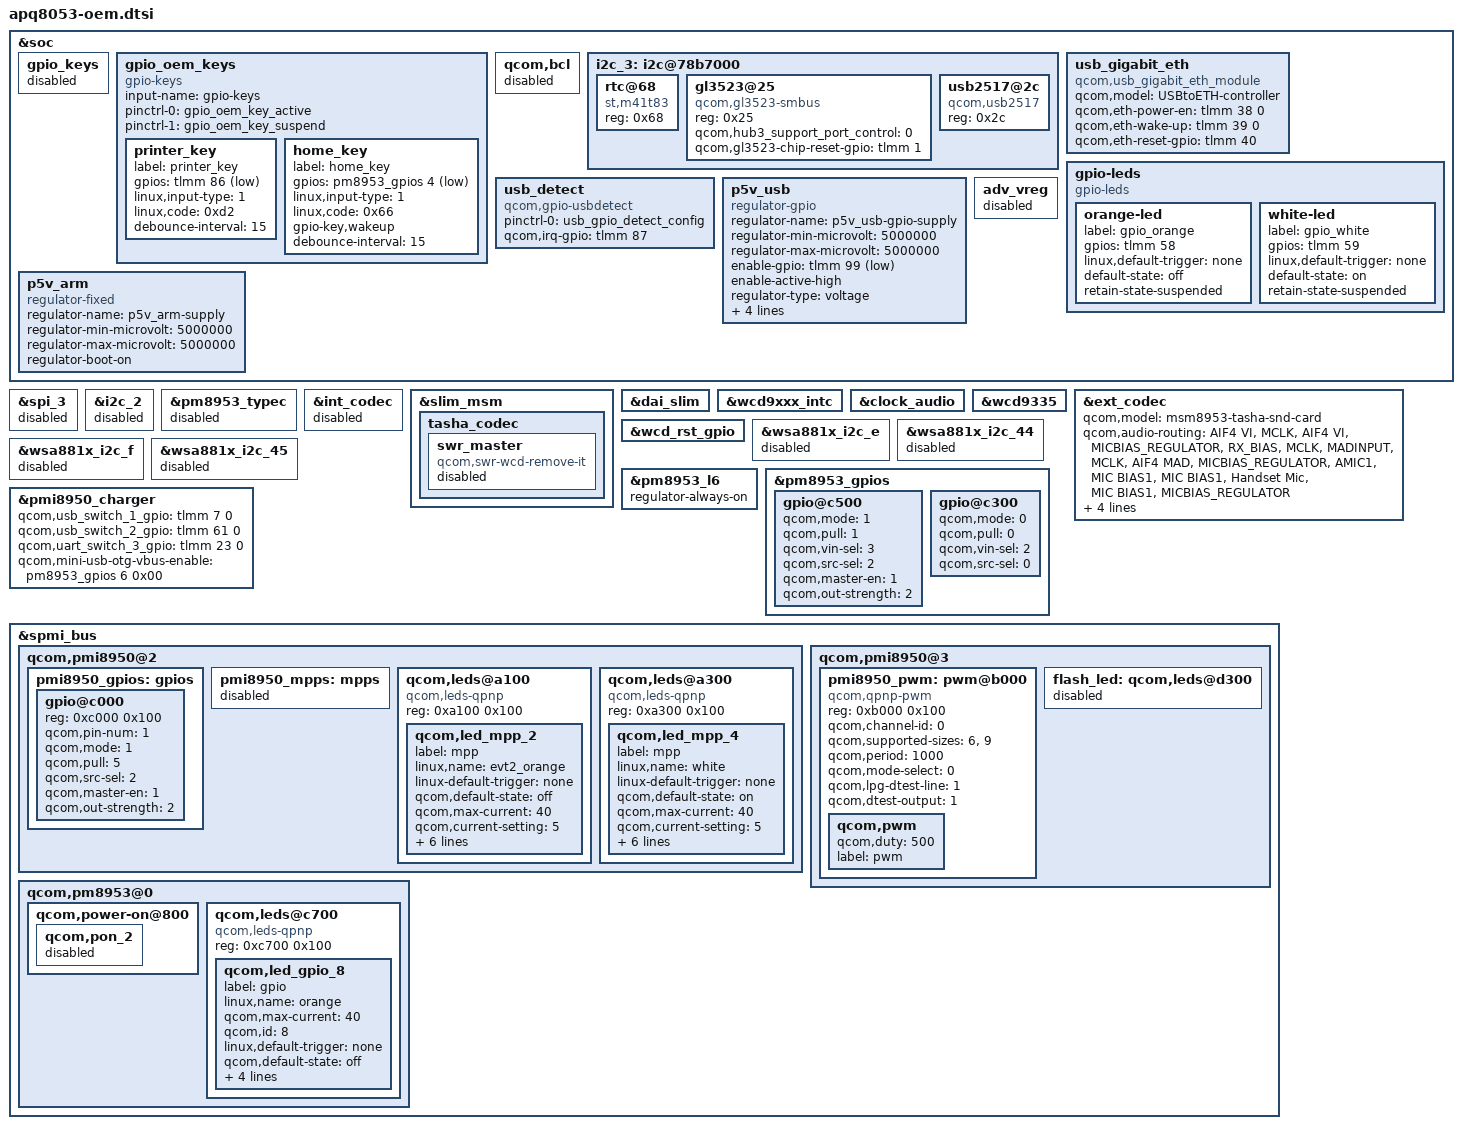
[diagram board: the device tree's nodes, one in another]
/*
 * Copyright (c) 2015-2016, The Linux Foundation. All rights reserved.
 *
 * This program is free software; you can redistribute it and/or modify
 * it under the terms of the GNU General Public License version 2 and
 * only version 2 as published by the Free Software Foundation.
 *
 * This program is distributed in the hope that it will be useful,
 * but WITHOUT ANY WARRANTY; without even the implied warranty of
 * MERCHANTABILITY or FITNESS FOR A PARTICULAR PURPOSE.  See the
 * GNU General Public License for more details.
 */


&soc {

/* Adil.Zhu, 2017/03/01, add dts info for home-key and printer-key {*/
	gpio_keys {
		status = "disabled";
	};

	gpio_oem_keys {
		compatible = "gpio-keys";
		input-name = "gpio-keys";
		pinctrl-names = "tlmm_gpio_key_active","tlmm_gpio_key_suspend";
		pinctrl-0 = <&gpio_oem_key_active>;
		pinctrl-1 = <&gpio_oem_key_suspend>;

		printer_key {
			label = "printer_key";
			gpios = <&tlmm 86 0x1>;
			linux,input-type = <1>;
			linux,code = <0xd2>; // 210 - KEY_PRINT
			debounce-interval = <15>;
		};

		home_key {
			label = "home_key";
			gpios = <&pm8953_gpios 4 0x1>;
			linux,input-type = <1>;
			linux,code = <0x66>; // 102
			gpio-key,wakeup;
			debounce-interval = <15>;
		};
	};

/* Adil.Zhu, 2017/03/01, add dts info for home-key and printer-key }*/

	/*20170308,Tony.L.Cai,disable BCL{*/
	qcom,bcl {
		status = "disabled";
	};
	/*}20170308,Tony.L.Cai,disable BCL*/

	i2c_3: i2c@78b7000 { /* BLSP1 QUP3 */
	status = "okay";

		/* OEM 2017/01/11, Jack W Lu, add RTC m41t83{ */
		rtc@68 {
			compatible = "st,m41t83";
			reg = <0x68>;
		};
		/* OEM 2017/01/11, Jack W Lu, add RTC m41t83} */
	};

/* OEM, Jerry.Zhai, 2017/09/12, usb gigabit ethernet pwr control {*/
	usb_gigabit_eth {
		compatible = "qcom,usb_gigabit_eth_module";
		qcom,model = "USBtoETH-controller";
		qcom,eth-power-en = <&tlmm 38 0>;  /* USB Gigabit Ethernet vbus pin: High enable*/
		qcom,eth-wake-up = <&tlmm 39 0>;  /* USB Gigabit Ethernet wakeup pin: Low Active*/
		qcom,eth-reset-gpio = <&tlmm 40 0>;  /* USB Gigabit Ethernet reset pin: Low Active*/
	};
/* OEM, Jerry.Zhai, 2017/01/09, usb gigabit ethernet pwr control }*/

/* pp, Tony.L.Cai, 2017/03/23, gpio leds porting{*/

	gpio-leds {
		compatible = "gpio-leds";

		orange-led {
			label="gpio_orange";
			gpios = <&tlmm 58 0>;
			linux,default-trigger = "none";
			default-state = "off";
			retain-state-suspended;
		};

		white-led {
			label="gpio_white";
			gpios = <&tlmm 59 0>;
			linux,default-trigger = "none";
			default-state = "on";
			retain-state-suspended;
		};
	};
/* pp, Tony.L.Cai, 2017/03/23, gpio leds porting}*/

	/* Carl add for vbus detect on gpio87 {*/
	usb_detect{
		compatible = "qcom,gpio-usbdetect";
		pinctrl-names = "default";
		pinctrl-0 = <&usb_gpio_detect_config>;

		qcom,irq-gpio = <&tlmm 87 0>;
	};
	/* Carl add for vbus detect on gpio87 }*/

/*pp, tony.l.cai, 20170605, gpio regulator enable for p5v_usb{*/
	p5v_usb: p5v_usb{
		compatible = "regulator-gpio";
		regulator-name = "p5v_usb-gpio-supply";
		regulator-min-microvolt = <5000000>;
		regulator-max-microvolt = <5000000>;
		enable-gpio = <&tlmm 99 1>;
		enable-active-high;
		regulator-type= "voltage";
		enable-at-boot;
		regulator-boot-on;
		gpios = <0>;
		states = <5000000 0x1
							0 0x0>;
	};
/*}pp, tony.l.cai, 20170605, gpio regulator enable for p5v_usb*/

/*OEM, Terry.Yan, 20171127, add fixed regulator for p5v_arm (RTC/HDMI){*/
	p5v_arm: p5v_arm {
		compatible = "regulator-fixed";
		regulator-name = "p5v_arm-supply";
		regulator-min-microvolt = <5000000>;
		regulator-max-microvolt = <5000000>;
		regulator-boot-on;
	};
/*OEM, Terry.Yan, 20171127, add fixed regulator for p5v_arm (RTC/HDMI){*/

/*OEM, Terry.Yan, 20171106, disable adv_vreg that controled by PM8953 GPIO 5 {*/
	adv_vreg: adv_vreg {
		status = "disabled";
	};
/*OEM, Terry.Yan, 20171106, disable adv_vreg that controled by PM8953 GPIO 5 }*/
};


&spi_3 {
	status = "disabled";
};

&i2c_2 {
	status = "disabled";
};

&pm8953_typec {
	status = "disabled";
};

/*20161208 Jack W Lu: Add for audio setting {*/
&int_codec {
	status = "disabled";
};

&slim_msm {
	status = "okay";
};

&dai_slim {
	status = "okay";
};

&wcd9xxx_intc {
	status = "okay";
};

&clock_audio {
	status = "okay";
};

&wcd9335 {
	status = "okay";
};

&ext_codec {
	qcom,model = "msm8953-tasha-snd-card";

	qcom,audio-routing =
		"AIF4 VI", "MCLK",
		"AIF4 VI", "MICBIAS_REGULATOR",
		"RX_BIAS", "MCLK",
		"MADINPUT", "MCLK",
		"AIF4 MAD", "MICBIAS_REGULATOR",
		"AMIC1", "MIC BIAS1",
		"MIC BIAS1", "Handset Mic",
		"MIC BIAS1", "MICBIAS_REGULATOR";

	qcom,spk-amp-mute-gpio = <&tlmm 95 0>;/*AMP_MUTE:MUTE the speaker AMP*/
	qcom,spk-amp-enable-gpio = <&tlmm 96 0>;/*SPKR_EN:power on the speaker AMP*/
	qcom,msm-mbhc-hphl-swh = <1>;
	qcom,msm-mbhc-gnd-swh = <1>;

	status = "okay";
};

&wcd_rst_gpio {
	status = "okay";
};

&wsa881x_i2c_e {
	status = "disabled";
};

&wsa881x_i2c_44 {
	status = "disabled";
};

&wsa881x_i2c_f {
	status = "disabled";
};

&wsa881x_i2c_45 {
	status = "disabled";
};
/*20161208 Jack W Lu: Add for audio setting }*/

/*20161226 Jack W Lu: Add for audio speaker AMP level shift {*/
&pm8953_l6 {
	regulator-always-on;
};
/*20161226 Jack W Lu: Add for audio speaker AMP level shift }*/

/*20161228 Jack W Lu: mini USB OTG device VBUS enable---Mini_USB_EN {*/
&pm8953_gpios {
	gpio@c500 {
		/* GPIO 6 (Mini_USB_EN) */
		status = "ok";
		qcom,mode = <1>;
		qcom,pull = <1>;//QPNP_PIN_PULL_UP_1P5
		qcom,vin-sel = <3>;//QPNP_PIN_VIN3, 3 = VREG_L5, 1.8V
		qcom,src-sel = <2>;//QPNP_PIN_SEL_FUNC_1
		qcom,master-en = <1>;
		qcom,out-strength = <2>;
	};
};
/*20161228 Jack W Lu: mini USB OTG device VBUS enable---Mini_USB_EN }*/

/*20161212 Jack W Lu: Add for USB switch control {*/
&pmi8950_charger {
	qcom,usb_switch_1_gpio = <&tlmm 7 0>;/*USB_Switch1_S: for ADB: L, for HOST: H*/
	qcom,usb_switch_2_gpio = <&tlmm 61 0>;/*USB_Switch2_S: for ADB: L, for HOST: H*/
	qcom,uart_switch_3_gpio = <&tlmm 23 0>;/*USB_Switch3_S: for UART: H, for HOST: L*/
	qcom,mini-usb-otg-vbus-enable = <&pm8953_gpios 6 0x00>;/*20161228 Jack W Lu: mini USB VBUS enable*/
};
/*20161212 Jack W Lu: Add for USB switch control }*/

/* OEM, 2017/03/05, Jack W Lu, add SMBUS for GL3523 { */
&i2c_3 {
	/*---all proj need GL3523, NOW for power and reset ONLY---*/
	gl3523@25 {
		compatible = "qcom,gl3523-smbus";
		reg = <0x25>;
		qcom,hub3_support_port_control = <0>; /*default: not support*/
		//qcom,p5v_usb_pwr_en_gpio = <&tlmm 99 1>;/*for P5V_USB_PWR_EN: High enable*/
		qcom,gl3523-chip-reset-gpio = <&tlmm 1 0>;/*for HUB GL3523 reset pin: LOW enable*/
	};

	/*ONLY PP1.5 EVT0 not enable*/
	usb2517@2c {
		compatible = "qcom,usb2517";
		reg = <0x2c>;
		/*qcom,usb2517-reset-gpio = <&tlmm 134 0>;for HUB2.0 usb2517 reset pin, need confirm the GPIO PIN*/
	};
};
/* OEM, 2017/03/05, Jack W Lu, add SMBUS for GL3523 } */

&pm8953_gpios {
/* OEM, Adil.Zhu, 2017/01/18, add dts info for home-key {*/
	gpio@c300 { /* GPIO 4 */
		qcom,mode = <0>;
		qcom,pull = <0>;
		qcom,vin-sel = <2>;
		qcom,src-sel = <0>;
		status = "okay";
	};
/* OEM, Adil.Zhu, 2017/01/18, add dts info for home-key }*/
};

&slim_msm {
	tasha_codec {
		swr_master {
			compatible = "qcom,swr-wcd-remove-it";
			status = "disabled";/*Jack W Lu:NOT used*/
		};
	};
};

&spmi_bus {

	qcom,pmi8950@2 {

		pmi8950_gpios: gpios {
			/* OEM 2016/12/12, Lewis Lin, change PWM @GPIO_1 { */
			gpio@c000 {
				reg = <0xc000 0x100>;
				qcom,pin-num = <1>;
				status = "okay";
				qcom,mode = <1>;
				qcom,pull = <5>;
				qcom,src-sel = <2>;
				qcom,master-en = <1>;
				qcom,out-strength = <2>;
			};
			/* OEM 2016/12/12, Lewis Lin, change PWM @GPIO_1 } */
		};

		/*OEM, 20171103, disable PMI8950 mpps(if you want to use pmi8950 mpps, please re-enable it{*/
		pmi8950_mpps: mpps {
			status = "disabled";
		};
		/*OEM, 20171103, disable PMI8950 mpps(if you want to use pmi8950 mpps, please re-enable it}*/

		qcom,leds@a100 {
			compatible = "qcom,leds-qpnp";
			reg = <0xa100 0x100>;
			status = "okay";
			qcom,led_mpp_2 {
				label = "mpp";
				linux,name = "evt2_orange";
				linux-default-trigger = "none";
				qcom,default-state = "off";
				qcom,max-current = <40>;
				qcom,current-setting=<5>;
				qcom,id = <6>;
				qcom,source-sel = <1>;
				qcom,mode-ctrl = <0x60>;
				qcom,vin-ctrl = <0x01>;//power domain:VPH_PWR
				qcom,min-brightness = <0>;
				qcom,mode = "manual";
			};
		};

		qcom,leds@a300 {
			compatible = "qcom,leds-qpnp";
			reg = <0xa300 0x100>;
			status = "okay";
			qcom,led_mpp_4 {
				label = "mpp";
				linux,name = "white";
				linux-default-trigger = "none";
				qcom,default-state = "on";
				qcom,max-current = <40>;
				qcom,current-setting=<5>;
				qcom,id = <6>;
				qcom,source-sel = <1>;
				qcom,mode-ctrl = <0x60>;
				qcom,vin-ctrl = <0x01>;//power domain:VPH_PWR
				qcom,min-brightness = <0>;
				qcom,mode = "manual";
			};
		};
		/* Adil.Zhu, 20170115, add dts info for led control } */
	};

	qcom,pmi8950@3 {
		/* OEM 2016/12/12, Lewis Lin,	add PWM @GPIO_1 , { */
			pmi8950_pwm: pwm@b000 {
			status = "okay";
			compatible = "qcom,qpnp-pwm";
			reg = <0xb000 0x100>;
			reg-names = "qpnp-lpg-channel-base";
			qcom,channel-id = <0>;
			qcom,supported-sizes = <6>, <9>;
			qcom,period = <1000>; //PWM period time in microseconds // Adds this line too.
			qcom,mode-select = <0>;
			qcom,lpg-dtest-line = <1>;
			qcom,dtest-output = <1>;
			qcom,pwm {
				qcom,duty = <500>; //PWM duty time in microseconds
				label = "pwm";
			};
		};
		/* OEM 2016/12/12, Lewis Lin,	add PWM @GPIO_1 , } */

		flash_led: qcom,leds@d300 {
			status = "disabled";
		};
	};

	/*OEM,20170404, disabe qpnp-power-on KEY_VOLUMEDOWN*/
	qcom,pm8953@0 {
		qcom,power-on@800 {
			qcom,pon_2 {
				status = "disabled";
			};
		};
		/*pp,Tony.L.Cai,20170412,change for pm8953 gpio led{*/
		qcom,leds@c700 {
		compatible = "qcom,leds-qpnp";
		reg = <0xc700 0x100>;
		status = "okay";
			qcom,led_gpio_8 {
				label = "gpio";
				linux,name = "orange";
				qcom,max-current = <40>;
				qcom,id = <8>;
				linux,default-trigger = "none";
				qcom,default-state = "off";
				qcom,turn-off-delay-ms = <1000>;
				qcom,source-sel = <1>;
				qcom,mode-ctrl = <0x10>;
				qcom,vin-ctrl = <0x01>;//power domain:VPH_PWR
			};
		};
		/*}pp,Tony.L.Cai,20170412,change for pm8953 gpio led*/
	};
};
